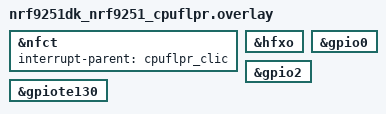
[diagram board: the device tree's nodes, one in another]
/*
 * Copyright (c) 2026 Nordic Semiconductor ASA
 *
 * SPDX-License-Identifier: LicenseRef-Nordic-5-Clause
 */

&nfct {
	status = "okay";
	interrupt-parent = <&cpuflpr_clic>;
};

&hfxo {
	status = "okay";
};

&gpio0 {
	status = "okay";
};

&gpio2 {
	status = "okay";
};

&gpiote130 {
	status = "okay";
};
